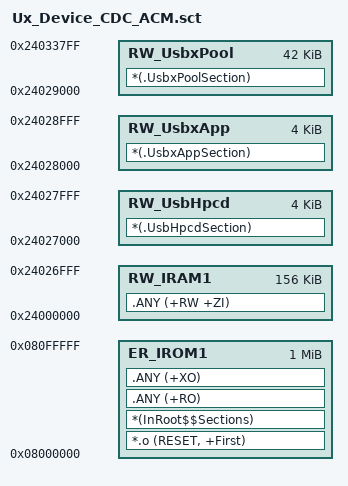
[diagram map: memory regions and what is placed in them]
; *************************************************************
; *** Scatter-Loading Description File generated by uVision ***
; *************************************************************

LR_IROM1 0x08000000 0x00100000  {    ; load region size_region
  ER_IROM1 0x08000000 0x00100000  {  ; load address = execution address
   *.o (RESET, +First)
   *(InRoot$$Sections)
   .ANY (+RO)
   .ANY (+XO)
  }
  RW_IRAM1 0x24000000 0x27000 {
   .ANY (+RW +ZI)
  }
  RW_UsbHpcd 0x24027000 0x1000 {
  *(.UsbHpcdSection)
  }
  RW_UsbxApp 0x24028000 0x1000 {
  *(.UsbxAppSection)
  }
  RW_UsbxPool 0x24029000 0xA800 {
  *(.UsbxPoolSection)
  }
}

